# D1H.pdf register map
Vendor: Allwinner; Series: D1H.pdf; File version: 0.1
CPU: XuanTie C906 RISC-V CPU 0, little endian, MPU, FPU, double-precision FPU, 0 interrupt priority bits
Registers are 32-bit, read-write, reset 0x0 unless marked. A register's access mark holds for its fields unless they carry their own. Offsets are from the block's base; [hi:lo] are bit positions.

## CSIC_DMA0
Base 0x05809000
Same registers: CSIC_DMA1 0x05809200
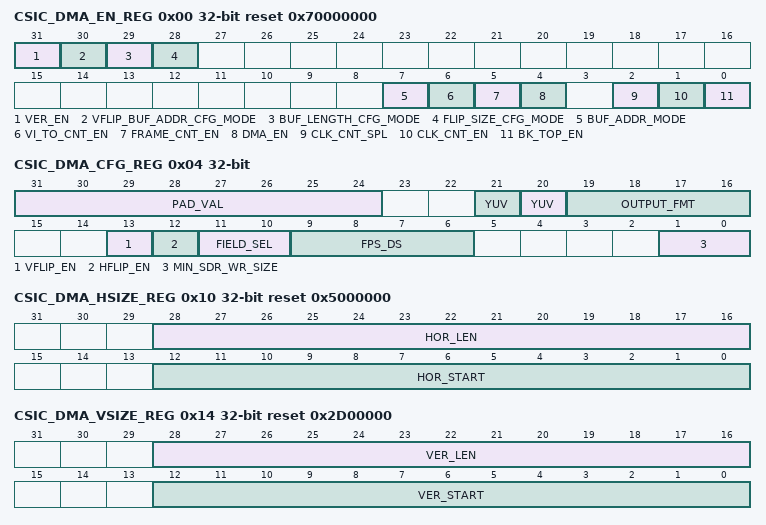
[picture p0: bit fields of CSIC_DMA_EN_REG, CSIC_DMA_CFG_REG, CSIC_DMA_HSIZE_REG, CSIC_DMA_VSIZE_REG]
0x00 CSIC_DMA_EN_REG reset 0x70000000 — CSIC DMA Enable Register
  [31] VER_EN
  [30] VFLIP_BUF_ADDR_CFG_MODE — Vflip buffer address set by software or calculated by hardware 0: Hardware 1: Software
    0=Hardware; 1=Software
  [29] BUF_LENGTH_CFG_MODE — Buffer length set by software or calculated by hardware 0: Hardware 1: Software
    0=Hardware; 1=Software
  [28] FLIP_SIZE_CFG_MODE — FLIP SIZE set by software or calculated by hardware 0: Hardware 1: Software
    0=Hardware; 1=Software
  [7] BUF_ADDR_MODE — 0: Buffer Address Register Mode 1: Buffer Address FIFO Mode
    0=Buffer Address Register Mode; 1=Buffer Address FIFO Mode
  [6] VI_TO_CNT_EN — Enable Video Input Timeout counter, add 1 when there is no effective video input in a 12M clock, clear to 0 when detecting effective video input. 0: Disable 1: Enable
    0=Disable; 1=Enable
  [5] FRAME_CNT_EN — When BK_TOP_EN is enabled, setting 1 to this bit indicates the Frame counter starts to add. 0: Disable 1: Enable
    0=Disable; 1=Enable
  [4] DMA_EN — When BK_TOP_EN is enabled, setting 1 to this bit indicates the module works in DMA mode. 0: Disable 1: Enable
    0=Disable; 1=Enable
  [2] CLK_CNT_SPL — Sampling time for clk counter per frame 0: Sampling clock counter every frame done 1: Sampling clock counter every vsync
    0=Sampling clock counter every frame done; 1=Sampling_clock_counter_every_vsync
  [1] CLK_CNT_EN — clk count per frame enable
  [0] BK_TOP_EN — 0: Disable 1: Enable
    0=Disable; 1=Enable
0x04 CSIC_DMA_CFG_REG — CSIC DMA Configuration Register
  [31:24] PAD_VAL — Padding value when OUTPUT_FMT is prgb888 0x00–0xff
  [21] YUV — 10-bit input cut to 8-bit 0: Disable 1: Enable
    0=Disable; 1=Enable
  [20] YUV — 10-bit store configuration 0: YUV 10-bit stored in low 10-bit of a 16-bit word 1: YUV 10-bit stored in high 10-bit of a 16-bit word
    0=10_bit_stored_in_low (YUV 10-bit stored in low 10-bit of a 16-bit word); 1=10_bit_stored_in_high (YUV 10-bit stored in high 10-bit of a 16-bit word)
  [19:16] OUTPUT_FMT — Output data format When the input format is set to RAW stream 0000: field-raw-8 0001: field-raw-10 0010: field-raw-12 0011: reserved 0100: field-rgb565 0101: field-rgb888 0110: field-prgb888 0111: reserved 1000: frame-raw-8 1001: frame-raw-10 1010: frame-raw-12 1011: reserved 1100: frame-rgb565 1101: frame-rgb888 1110: frame-prgb888 1111: reserved When the input format is set to YUV422 0000: field planar YCbCr 422 0001: field planar YCbCr 420 0010: frame planar YCbCr 420 0011: frame planar YCbCr 422 0100: field planar YCbCr 422 UV combined (UV sequence) 0101: field planar YCbCr 420 UV combined (UV sequence) 0110: frame planar YCbCr 420 UV combined (UV sequence) 0111: frame planar YCbCr 422 UV combined (UV sequence) 1000: filed planar YCbCr 422 UV combined (VU sequence) 1001: field planar YCbCr 420 UV combined (VU sequence) 1010: frame planar YCbCr 420 UV combined (VU sequence) 1011: frame planar YCbCr 422 UV combined (VU sequence) 1100: reserved 1101: field YCbCr 400 1110: reserved 1111: frame YCbCr 400 When the input format is set to YUV420 0000: reserved 0001: field planar YCbCr 420 0010: frame planar YCbCr 420 0011: reserved 0100: reserved 0101: field planar YCbCr 420 UV combined (UV sequence) 0110: frame planar YCbCr 420 UV combined (UV sequence) 0111~1000: reserved 1001: field planar YCbCr 420 UV combined (VU sequence) 1010: frame planar YCbCr 420 UV combined (VU sequence) 1011~1100: reserved 1101: field YCbCr 400 1110: reserved 1111: frame YCbCr 400
  [13] VFLIP_EN — Vertical flip enable When enabled, the received data will be arranged in vertical flip. 0: Disable 1: Enable
    0=Disable; 1=Enable
  [12] HFLIP_EN — Horizontal flip enable When enabled, the received data will be arranged in horizontal flip. 0: Disable 1: Enable
    0=Disable; 1=Enable
  [11:10] FIELD_SEL — Field selection 00: Capturing with field 0 01: Capturing with field 1 10: Capturing with either field 11: Reserved
    0=Capturing_with_field_0; 1=Capturing_with_field_1; 2=Capturing_with_either_field
  [9:6] FPS_DS — Fps down sample 0: no down sample 1: 1/2 fps, only receives the first frame every 2 frames 2: 1/3 fps, only receives the first frame every 3 frames 3: 1/4 fps, only receives the first frame every 4 frames 4: 1/5 fps, only receives the first frame every 4 frames …… 15: 1/16 fps, only receives the first frame every 16 frames
    2=_1_slash_3 (1/3 fps, only receives the first frame every 3 frames); 3=_1_slash_4 (1/4 fps, only receives the first frame every 4 frames); 4=_1_slash_5 (1/5 fps, only receives the first frame every 4 frames ……); 15=_1_slash_16 (1/16 fps, only receives the first frame every 16 frames)
  [1:0] MIN_SDR_WR_SIZE — Minimum size of SDRAM block write 00: 256 bytes (if hflip is enabled, always select 256 bytes) 01: 512 bytes 10: 1K bytes 11: 2K bytes
    0=256 bytes (if hflip is enabled, always select 256 bytes); 1=512 bytes; 2=_1K (1K bytes); 3=_2K (2K bytes)
0x10 CSIC_DMA_HSIZE_REG reset 0x5000000 — CSIC DMA Horizontal Size Register
  [28:16] HOR_LEN — When BK_TOP_EN is enabled, DMA_EN is enabled, these bits indicate Horizontal pixel unit length. Valid pixel of a line in DMA mode.
  [12:0] HOR_START — Horizontal pixel unit start. Pixel is valid from this pixel.
0x14 CSIC_DMA_VSIZE_REG reset 0x2D00000 — CSIC DMA Vertical Size Register
  [28:16] VER_LEN — When BK_TOP_EN is enabled, DMA_EN is enabled, these bits indicate Valid line number of a frame in DMA mode.
  [12:0] VER_START — Vertical line start Data is valid from this line.
0x20 CSIC_DMA_F0_BUFA_REG — CSIC DMA FIFO 0 Output Buffer-A Address Register
  [31:0] F0_BUFA — When BK_TOP_EN is enabled, FBC_EN is enabled, DMA_EN is disabled, these bits indicate output address of overhead data in FBC mode. When BK_TOP_EN is enabled, FBC_EN is disabled, DMA_EN is enabled, LBC_EN is disabled, these bits indicate FIFO 0 output buffer-A address in DMA mode. When BK_TOP_EN is enabled, FBC_EN is disabled, DMA_EN is enabled, LBC_EN is enabled, these bits indicate the output buffer address in LBC mode.
0x24 CSIC_DMA_F0_BUFA_RESULT_REG — CSIC DMA FIFO 0 Output Buffer-A Address Result Register
  [31:0] F0_BUFA_RESULT ro — Indicate the final F0_BUFA address used for DMA or FBC after software configuration or hardware calculation from Buffer-A address register or buffer address fifo. Only used for debug.
0x28 CSIC_DMA_F1_BUFA_REG — CSIC DMA FIFO 1 Output Buffer-A Address Register
  [31:0] F1_BUFA — When BK_TOP_EN is enabled, FBC_EN is enabled, DMA_EN is disabled, these bits indicate the output address of compressed data in FBC mode. When BK_TOP_EN is enabled, FBC_EN is disabled, DMA_EN is enabled, these bits indicate the FIFO 1 output buffer-A address in DMA mode.
0x2C CSIC_DMA_F1_BUFA_RESULT_REG — CSIC DMA FIFO 2 Output Buffer-A Address Result Register
  [31:0] F1_BUFA_RESULT ro — Indicate the final F1_BUFA address used for DMA or FBC after software configuration or hardware calculation from Buffer-A address register or buffer address fifo. Only used for debug.
0x30 CSIC_DMA_F2_BUFA_REG — CSIC DMA FIFO 2 Output Buffer-A Address Register
  [31:0] F2_BUFA — FIFO 2 output buffer-A address.
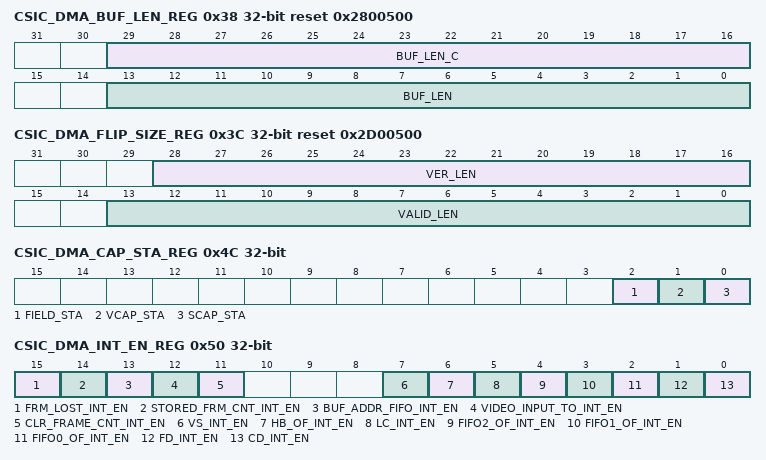
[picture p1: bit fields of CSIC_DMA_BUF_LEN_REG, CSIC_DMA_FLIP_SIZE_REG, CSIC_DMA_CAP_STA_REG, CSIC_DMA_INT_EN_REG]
0x38 CSIC_DMA_BUF_LEN_REG reset 0x2800500 — CSIC DMA Buffer Length Register
  [29:16] BUF_LEN_C — DMA_MODE: Buffer length of chroma C in a line. Unit is byte. LBC_MODE: Buffer length Stride of luminance Y in ONLY Y line. Unit is byte. Only Readable when BUF_LENGTH_CFG_MODE is set 0.
  [13:0] BUF_LEN — DMA_MODE:Buffer length of luminance Y in a line. Unit is byte. LBC_MODE: Buffer length Stride of luminance Y and chroma C in YC line. Unit is byte. Only Readable when BUF_LENGTH_CFG_MODE is set 0.
0x3C CSIC_DMA_FLIP_SIZE_REG reset 0x2D00500 — CSIC DMA Flip Size Register
  [28:16] VER_LEN — Vertical line number when in VFLIP mode. Unit is line. Only Readable when FLIP_SIZE_CFG_MODE is set to 0.
  [13:0] VALID_LEN — Valid components of a line when in HFLIP mode. Unit is pixel component. Only Readable when FLIP_SIZE_CFG_MODE is set to 0.
0x40 CSIC_DMA_VI_TO_TH0_REG — CSIC DMA Video Input Timeout Threshold0 Register
  [31:0] VIDEO — Video Input Timeout Threshold0 Set VIDEO_INPUT_TO_INT_PD when VI Counter reaches TH0 after VI_TO_CNT_EN is set, the Time Unit is a 12M clock period.
0x44 CSIC_DMA_VI_TO_TH1_REG — CSIC DMA Video Input Timeout Threshold1 Register
  [31:0] VIDEO — Video Input Timeout Threshold1 Set VIDEO_INPUT_TO_INT_PD when VI Counter reaches TH1 after getting the first frame has been input, the Time Unit is a 12M clock period.
0x48 CSIC_DMA_VI_TO_CNT_VAL_REG — CSIC DMA Video Input Timeout Counter Value Register
  [31:0] VIDEO ro — Video Input Timeout Counter Value Indicate the current value of Video Input Timeout Counter
0x4C CSIC_DMA_CAP_STA_REG — CSIC DMA Capture Status Register
  [2] FIELD_STA ro — The status of the received field 0: Field 0 1: Field 1
    0=Field_0; 1=Field_1
  [1] VCAP_STA ro — Video capture in progress Indicates the CSI is capturing video image data (multiple frames). The bit is set at the start of the first frame after enabling video capture. When software disables video capture, it clears itself after the last pixel of the current frame is captured.
  [0] SCAP_STA ro — Still capture in progress Indicates the CSI is capturing still image data (single frame). The bit is set at the start of the first frame after enabling still frame capture. It clears itself after the last pixel of the first frame is captured. For CCIR656 interface, if the output format is frame planar YCbCr 420 mode, the frame end means the field2 end, the other frame end means filed end.
0x50 CSIC_DMA_INT_EN_REG — CSIC DMA Interrupt Enable Register
  [15] FRM_LOST_INT_EN — Set an INT when frame starts with empty Buffer Address FIFO, only use in BUF Address FIFO MODE.
  [14] STORED_FRM_CNT_INT_EN — Set an INT when the value of CSIC_DMA_STORED_FRM_CNT reaches CSIC_DMA_STORED_FRM_THRESHOLD, only use in BUF Address FIFO MODE.
  [13] BUF_ADDR_FIFO_INT_EN — Set an INT when content in BUF Address FIFO less than CSIC_DMA_BUFA_FIFO_THRESHOLD, only use in BUF Address FIFO MODE.
  [12] VIDEO_INPUT_TO_INT_EN — Set an INT when no video input exceeds the setting threshold time
  [11] CLR_FRAME_CNT_INT_EN — Set a INT when clear Frame cnt.
  [7] VS_INT_EN — vsync flag The bit is set when vsync come. And at this time load the buffer address for the coming frame. So after this irq come, changing the buffer address could only effect next frame
  [6] HB_OF_INT_EN — Hblank FIFO overflow The bit is set when 3 FIFOs still overflow after the hblank.
  [5] LC_INT_EN — Line counter flag The bit is set when the specific line has been written to dram every frame. The line number is set in the line counter register.
  [4] FIFO2_OF_INT_EN — FIFO 2 overflow The bit is set when the FIFO 2 became overflow.
  [3] FIFO1_OF_INT_EN — FIFO 1 overflow The bit is set when the FIFO 1 became overflow.
  [2] FIFO0_OF_INT_EN — FIFO 0 overflow The bit is set when the FIFO 0 became overflow.
  [1] FD_INT_EN — Frame done Indicates the CSI has finished capturing an image frame. Applies to video capture mode. The bit is set after each completed frame capturing data is written to buffer as long as video capture remains enabled.
  [0] CD_INT_EN — Capture done Indicates the CSI has completed capturing the image data. For still capture, the bit is set when one frame data has been written to buffer. For video capture, the bit is set when the last frame has been written to buffer after video capture has been disabled. For CCIR656 interface, if the output format is frame planar YCbCr 420 mode, the frame end means the field2 end, the other frame end means field end.
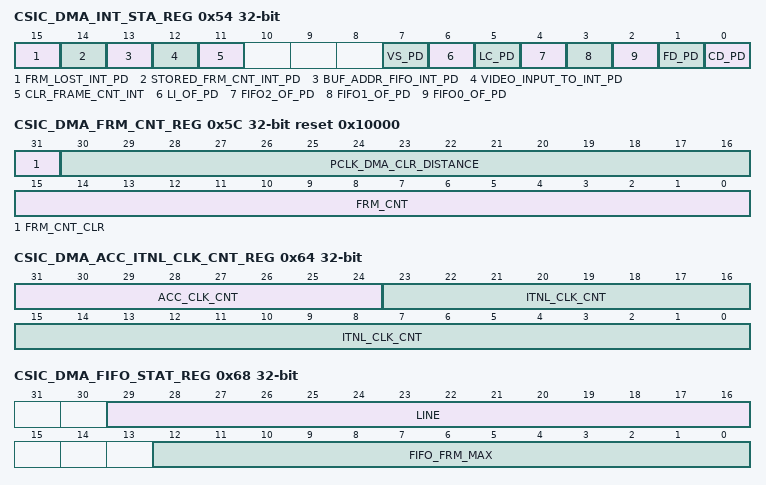
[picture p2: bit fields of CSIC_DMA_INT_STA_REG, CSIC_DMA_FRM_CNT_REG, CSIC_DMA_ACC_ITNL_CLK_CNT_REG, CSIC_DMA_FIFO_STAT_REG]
0x54 CSIC_DMA_INT_STA_REG — CSIC DMA Interrupt Status Register
  [15] FRM_LOST_INT_PD write-1-clears — Set an INT when frame starts with empty Buffer Address FIFO, only use in BUF Address FIFO MODE.
  [14] STORED_FRM_CNT_INT_PD write-1-clears — Set an INT when the value of CSIC_DMA_STORED_FRM_CNT reaches CSIC_DMA_STORED_FRM_THRESHOLD, only use in BUF Address FIFO MODE.
  [13] BUF_ADDR_FIFO_INT_PD write-1-clears — Set an INT when content in BUF Address FIFO less than CSIC_DMA_BUFA_FIFO_THRESHOLD, only use in BUF Address FIFO MODE.
  [12] VIDEO_INPUT_TO_INT_PD write-1-clears — Set an INT Pending when no video input exceeds the setting threshold time.
  [11] CLR_FRAME_CNT_INT write-1-clears — Set a INT when clear Frame cnt.
  [7] VS_PD write-1-clears — vsync flag
  [6] LI_OF_PD write-1-clears — Line information FIFO (16 lines) overflow
  [5] LC_PD write-1-clears — Line counter flag
  [4] FIFO2_OF_PD write-1-clears — FIFO 2 overflow
  [3] FIFO1_OF_PD write-1-clears — FIFO 1 overflow
  [2] FIFO0_OF_PD write-1-clears — FIFO 0 overflow
  [1] FD_PD write-1-clears — Frame done
  [0] CD_PD write-1-clears — Capture done
0x58 CSIC_DMA_LINE_CNT_REG — CSIC DMA LINE Counter Register
  [12:0] LINE_CNT_NUM — The LINE_CNT_NUM value is set by user,when internal line counter reach the set value, the LC_PD will be set.
0x5C CSIC_DMA_FRM_CNT_REG reset 0x10000 — CSIC DMA Frame Counter Register
  [31] FRM_CNT_CLR write-1-clears — When the bit set to 1, Frame cnt is cleared to 0.
  [30:16] PCLK_DMA_CLR_DISTANCE — Frame cnt clear cycle N*T
  [15:0] FRM_CNT ro — Counter value of frame. When frame done comes, the internal counter value add 1, and when the reg full, it is cleared to 0 . When parser sent a sync signal, it is cleared to 0.
0x60 CSIC_DMA_FRM_CLK_CNT_REG — CSIC DMA Frame Clock Counter Register
  [23:0] FRM_CLK_CNT ro — Counter value between every frame. For instant hardware frame rate statics. The internal counter is added by one every 12 MHz clock cycle. When frame done or vsync comes, the internal counter value is sampled to FRM_CLK_CNT, and cleared to 0.
0x64 CSIC_DMA_ACC_ITNL_CLK_CNT_REG
  [31:24] ACC_CLK_CNT write-clears — The accumulated value of FRM_CLK_CNT for software frame rate statics. Every interrupt of frame is done, the software checks this accumulated value and clears it to 0. If the ACC_CLK_CNT is larger than 1, the software has lost frame. When frame done or vsync comes, ACC_CLK_CNT = ACC_CLK_CNT + 1, and cleared to 0 when writing this register.
  [23:0] ITNL_CLK_CNT ro — The instant value of internal frame clock counter. When frame done interrupt comes, the software can query this counter for judging whether it is the time for updating the double buffer address registers.
0x68 CSIC_DMA_FIFO_STAT_REG — CSIC DMA FIFO Statistic Register
  [29:16] LINE ro — Line Index Indicates the line index in current vsync.
  [12:0] FIFO_FRM_MAX ro — Indicates the maximum depth of FIFO being occupied for whole frame. Update at every vsync or framedone.
0x6C CSIC_DMA_FIFO_THRS_REG reset 0x400 — CSIC DMA FIFO Threshold Register
  [11:0] FIFO_THRS — When FIFO occupied memory exceed the threshold, dram frequency can not change.
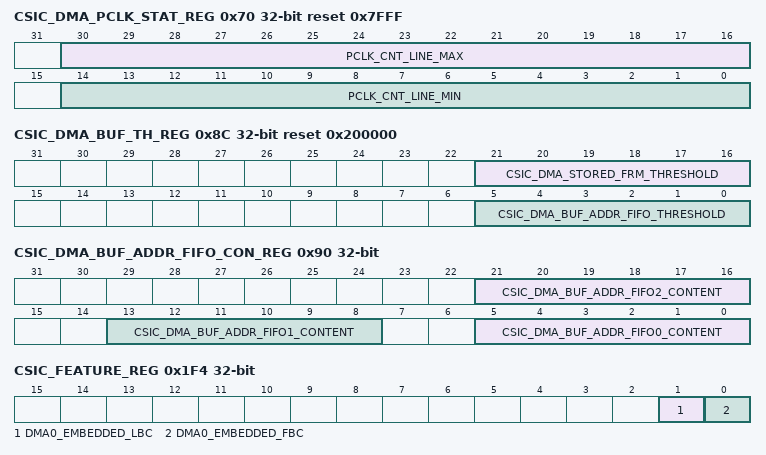
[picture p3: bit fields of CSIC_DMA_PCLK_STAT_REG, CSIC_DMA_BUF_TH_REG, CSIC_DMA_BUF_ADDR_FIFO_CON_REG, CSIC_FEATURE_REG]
0x70 CSIC_DMA_PCLK_STAT_REG reset 0x7FFF — CSIC DMA PCLK Statistic Register
  [30:16] PCLK_CNT_LINE_MAX ro — Indicates maximum pixel clock counter value for each line. Update at every vsync or framedone.
  [14:0] PCLK_CNT_LINE_MIN ro — Indicates minimum pixel clock counter value for each line. Update at every vsync or framedone.
0x80 CSIC_DMA_BUF_ADDR_FIFO0_ENTRY_REG
  [31:0] CSIC_DMA_BUF_ADDR_FIFO0_ENTRY — FIFO Entry of Buffer Address FIFO0 for input frames to be stored, only used in Buffer Addr FIFO Mode
0x84 CSIC_DMA_BUF_ADDR_FIFO1_ENTRY_REG
  [31:0] CSIC_DMA_BUF_ADDR_FIFO1_ENTRY — FIFO Entry of Buffer Address FIFO1 for input frames to be stored, only used in Buffer Addr FIFO Mode.
0x88 CSIC_DMA_BUF_ADDR_FIFO2_ENTRY_REG
  [31:0] CSIC_DMA_BUF_ADDR_FIFO2_ENTRY — FIFO Entry of Buffer Address FIFO2 for input frames to be stored, only used in Buffer Addr FIFO Mode.
0x8C CSIC_DMA_BUF_TH_REG reset 0x200000 — CSIC DMA BUF Threshold Register
  [21:16] CSIC_DMA_STORED_FRM_THRESHOLD — when stored frame counter value reaches the threshold , counter is cleared to 0 , only used in Buffer Addr FIFO Mode.
  [5:0] CSIC_DMA_BUF_ADDR_FIFO_THRESHOLD — when content in Buffer Address FIFO less than the threshold, an interrupt is set, only used in Buffer Addr FIFO Mode.
0x90 CSIC_DMA_BUF_ADDR_FIFO_CON_REG
  [21:16] CSIC_DMA_BUF_ADDR_FIFO2_CONTENT ro — FIFO Content of address buffered in Buffer Address FIFO2, only used in Buffer Addr FIFO Mode.
  [13:8] CSIC_DMA_BUF_ADDR_FIFO1_CONTENT ro — FIFO Content of address buffered in Buffer Address FIFO1, only used in Buffer Addr FIFO Mode.
  [5:0] CSIC_DMA_BUF_ADDR_FIFO0_CONTENT ro — FIFO Content of address buffered in Buffer Address FIFO0, only used in Buffer Addr FIFO Mode.
0x94 CSIC_DMA_STORED_FRM_CNT_REG — CSIC DMA Stored Frame Counter Register
  [7:0] CSIC_DMA_STORED_FRM_CNT ro — Indicates value of stored frames counter. When the counter value reaches CSIC_DMA_STORED_FRM_THRESHOLD, the counter is cleared to 0. Only used in Buffer Addr FIFO Mode.
0x1F4 CSIC_FEATURE_REG — CSIC DMA Feature List Register
  [1] DMA0_EMBEDDED_LBC ro — 0: No Embedded LBC 1: Embedded LBC
    0=No Embedded LBC; 1=Embedded LBC
  [0] DMA0_EMBEDDED_FBC ro — 0: No Embedded DMA 1: Embedded FBC
    0=No Embedded DMA; 1=Embedded FBC
